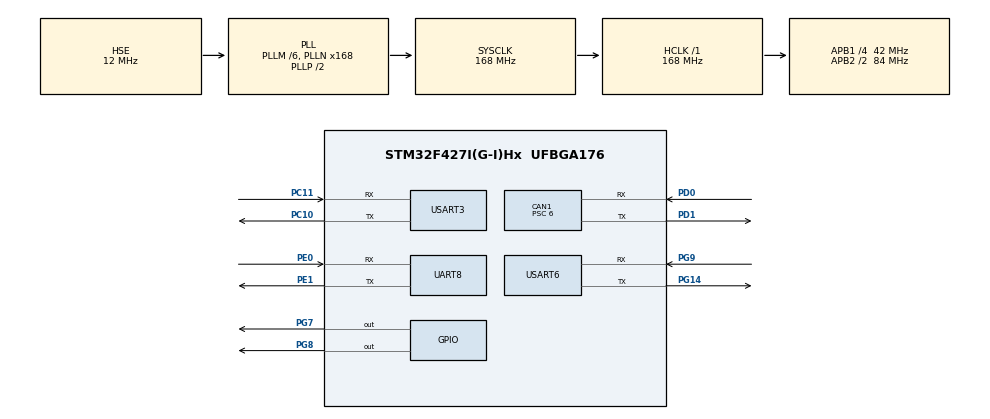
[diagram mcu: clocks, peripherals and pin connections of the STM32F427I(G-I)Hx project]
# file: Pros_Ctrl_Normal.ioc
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CAN1.BS1=CAN_BS1_4TQ
CAN1.BS2=CAN_BS2_2TQ
CAN1.CalculateBaudRate=1000000
CAN1.CalculateTimeBit=1000
CAN1.CalculateTimeQuantum=142.85714285714286
CAN1.Prescaler=6
Dma.Request0=USART6_RX
Dma.Request1=USART6_TX
Dma.Request2=USART3_RX
Dma.Request3=USART3_TX
Dma.Request4=UART8_TX
Dma.UART8_TX.4.Direction=DMA_MEMORY_TO_PERIPH
Dma.UART8_TX.4.FIFOMode=DMA_FIFOMODE_DISABLE
Dma.UART8_TX.4.Instance=DMA1_Stream0
Dma.UART8_TX.4.MemDataAlignment=DMA_MDATAALIGN_BYTE
Dma.UART8_TX.4.MemInc=DMA_MINC_ENABLE
Dma.UART8_TX.4.Mode=DMA_NORMAL
Dma.UART8_TX.4.PeriphDataAlignment=DMA_PDATAALIGN_BYTE
Dma.UART8_TX.4.PeriphInc=DMA_PINC_DISABLE
Dma.UART8_TX.4.Priority=DMA_PRIORITY_LOW
Dma.USART3_RX.2.Direction=DMA_PERIPH_TO_MEMORY
Dma.USART3_RX.2.FIFOMode=DMA_FIFOMODE_DISABLE
Dma.USART3_RX.2.Instance=DMA1_Stream1
Dma.USART3_RX.2.MemDataAlignment=DMA_MDATAALIGN_BYTE
Dma.USART3_RX.2.MemInc=DMA_MINC_ENABLE
Dma.USART3_RX.2.Mode=DMA_CIRCULAR
Dma.USART3_RX.2.PeriphDataAlignment=DMA_PDATAALIGN_BYTE
Dma.USART3_RX.2.PeriphInc=DMA_PINC_DISABLE
Dma.USART3_RX.2.Priority=DMA_PRIORITY_LOW
Dma.USART3_TX.3.Direction=DMA_MEMORY_TO_PERIPH
Dma.USART3_TX.3.FIFOMode=DMA_FIFOMODE_DISABLE
Dma.USART3_TX.3.Instance=DMA1_Stream3
Dma.USART3_TX.3.MemDataAlignment=DMA_MDATAALIGN_BYTE
Dma.USART3_TX.3.MemInc=DMA_MINC_ENABLE
Dma.USART3_TX.3.Mode=DMA_NORMAL
Dma.USART3_TX.3.PeriphDataAlignment=DMA_PDATAALIGN_BYTE
Dma.USART3_TX.3.PeriphInc=DMA_PINC_DISABLE
Dma.USART3_TX.3.Priority=DMA_PRIORITY_LOW
Dma.USART6_RX.0.Direction=DMA_PERIPH_TO_MEMORY
Dma.USART6_RX.0.FIFOMode=DMA_FIFOMODE_DISABLE
Dma.USART6_RX.0.Instance=DMA2_Stream1
Dma.USART6_RX.0.MemDataAlignment=DMA_MDATAALIGN_BYTE
Dma.USART6_RX.0.MemInc=DMA_MINC_ENABLE
Dma.USART6_RX.0.Mode=DMA_CIRCULAR
Dma.USART6_RX.0.PeriphDataAlignment=DMA_PDATAALIGN_BYTE
Dma.USART6_RX.0.PeriphInc=DMA_PINC_DISABLE
Dma.USART6_RX.0.Priority=DMA_PRIORITY_LOW
Dma.USART6_TX.1.Direction=DMA_MEMORY_TO_PERIPH
Dma.USART6_TX.1.FIFOMode=DMA_FIFOMODE_DISABLE
Dma.USART6_TX.1.Instance=DMA2_Stream6
Dma.USART6_TX.1.MemDataAlignment=DMA_MDATAALIGN_BYTE
Dma.USART6_TX.1.MemInc=DMA_MINC_ENABLE
Dma.USART6_TX.1.Mode=DMA_NORMAL
Dma.USART6_TX.1.PeriphDataAlignment=DMA_PDATAALIGN_BYTE
Dma.USART6_TX.1.PeriphInc=DMA_PINC_DISABLE
Dma.USART6_TX.1.Priority=DMA_PRIORITY_LOW
Mcu.Family=STM32F4
Mcu.Name=STM32F427I(G-I)Hx
Mcu.Package=UFBGA176
NVIC.CAN1_RX0_IRQn=true\:0\:0\:false\:false\:true\:true\:true\:true
NVIC.DMA1_Stream0_IRQn=true\:0\:0\:false\:false\:true\:false\:true\:true
NVIC.DMA1_Stream1_IRQn=true\:0\:0\:false\:false\:true\:false\:true\:true
NVIC.DMA1_Stream3_IRQn=true\:0\:0\:false\:false\:true\:false\:true\:true
NVIC.DMA2_Stream1_IRQn=true\:0\:0\:false\:false\:true\:false\:true\:true
NVIC.DMA2_Stream6_IRQn=true\:0\:0\:false\:false\:true\:false\:true\:true
NVIC.PriorityGroup=NVIC_PRIORITYGROUP_4
NVIC.TIM4_IRQn=true\:15\:0\:false\:false\:true\:false\:true\:true
NVIC.TimeBase=TIM4_IRQn
NVIC.TimeBaseIP=TIM4
NVIC.USART6_IRQn=true\:0\:0\:false\:false\:true\:true\:true\:true
PA13.Mode=Serial_Wire
PA13.Signal=SYS_JTMS-SWDIO
PA14.Mode=Serial_Wire
PA14.Signal=SYS_JTCK-SWCLK
PC10.Mode=Asynchronous
PC10.Signal=USART3_TX
PC11.Mode=Asynchronous
PC11.Signal=USART3_RX
PD0.Mode=CAN_Activate
PD0.Signal=CAN1_RX
PD1.Mode=CAN_Activate
PD1.Signal=CAN1_TX
PE0.Mode=Asynchronous
PE0.Signal=UART8_RX
PE1.Mode=Asynchronous
PE1.Signal=UART8_TX
PG14.Mode=Asynchronous
PG14.Signal=USART6_TX
PG7.Signal=GPIO_Output
PG8.Signal=GPIO_Output
PG9.Mode=Asynchronous
PG9.Signal=USART6_RX
PH0/OSC_IN.Mode=HSE-External-Oscillator
PH0/OSC_IN.Signal=RCC_OSC_IN
PH1/OSC_OUT.Mode=HSE-External-Oscillator
PH1/OSC_OUT.Signal=RCC_OSC_OUT
ProjectManager.HeapSize=0x200
ProjectManager.StackSize=0x400
ProjectManager.TargetToolchain=STM32CubeIDE
RCC.48MHZClocksFreq_Value=84000000
RCC.AHBFreq_Value=168000000
RCC.APB1CLKDivider=RCC_HCLK_DIV4
RCC.APB1Freq_Value=42000000
RCC.APB1TimFreq_Value=84000000
RCC.APB2CLKDivider=RCC_HCLK_DIV2
RCC.APB2Freq_Value=84000000
RCC.APB2TimFreq_Value=168000000
RCC.CortexFreq_Value=168000000
RCC.HCLKFreq_Value=168000000
RCC.HSE_VALUE=12000000
RCC.HSI_VALUE=16000000
RCC.LSE_VALUE=32768
RCC.PLLM=6
RCC.PLLN=168
RCC.PLLSourceVirtual=RCC_PLLSOURCE_HSE
RCC.SYSCLKFreq_VALUE=168000000
RCC.SYSCLKSource=RCC_SYSCLKSOURCE_PLLCLK
RCC.VCOOutputFreq_Value=336000000
UART8.VirtualMode=Asynchronous
USART3.VirtualMode=VM_ASYNC
USART6.VirtualMode=VM_ASYNC
VP_SYS_VS_tim4.Mode=TIM4
board=custom

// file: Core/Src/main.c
/* USER CODE BEGIN Header */
/**
  ******************************************************************************
  * @file           : main.c
  * @brief          : Main program body
  ******************************************************************************
  * @attention
  *
  * Copyright (c) 2023 STMicroelectronics.
  * All rights reserved.
  *
  * This software is licensed under terms that can be found in the LICENSE file
  * in the root directory of this software component.
  * If no LICENSE file comes with this software, it is provided AS-IS.
  *
  ******************************************************************************
  */
/* USER CODE END Header */
#include "main.h"
#include "can.h"
#include "dma.h"
#include "usart.h"
#include "gpio.h"

/* USER CODE BEGIN Includes */
#include "motor.h"
#include "uart_communication.h"
/* USER CODE END Includes */

void SystemClock_Config(void);

int main(void)
{

  /* MCU Configuration--------------------------------------------------------*/

  /* Reset of all peripherals, Initializes the Flash interface and the Systick. */
  HAL_Init();

  /* Configure the system clock */
  SystemClock_Config();

  /* Initialize all configured peripherals */
  MX_GPIO_Init();
  MX_DMA_Init();
  MX_USART6_UART_Init();
  MX_USART3_UART_Init();
  MX_CAN1_Init();
  MX_UART8_Init();
  /* USER CODE BEGIN 2 */
  CAN_FilterConfig();
  motor_init();
  Start_PCReceiveIT();
  /* USER CODE END 2 */

  /* Infinite loop */
  while (1)
  {

    /* USER CODE BEGIN 3 */
	  PC_PackMessage();
	  HAL_Delay(10);
	  Motor_Debug_CMDUnpack();
	  debugPrint("Hello\r\n");
  }
  /* USER CODE END 3 */
}

void SystemClock_Config(void)
{
  RCC_OscInitTypeDef RCC_OscInitStruct = {0};
  RCC_ClkInitTypeDef RCC_ClkInitStruct = {0};

  /** Configure the main internal regulator output voltage
  */
  __HAL_RCC_PWR_CLK_ENABLE();
  __HAL_PWR_VOLTAGESCALING_CONFIG(PWR_REGULATOR_VOLTAGE_SCALE1);

  /** Initializes the RCC Oscillators according to the specified parameters
  * in the RCC_OscInitTypeDef structure.
  */
  RCC_OscInitStruct.OscillatorType = RCC_OSCILLATORTYPE_HSE;
  RCC_OscInitStruct.HSEState = RCC_HSE_ON;
  RCC_OscInitStruct.PLL.PLLState = RCC_PLL_ON;
  RCC_OscInitStruct.PLL.PLLSource = RCC_PLLSOURCE_HSE;
  RCC_OscInitStruct.PLL.PLLM = 6;
  RCC_OscInitStruct.PLL.PLLN = 168;
  RCC_OscInitStruct.PLL.PLLP = RCC_PLLP_DIV2;
  RCC_OscInitStruct.PLL.PLLQ = 4;
  if (HAL_RCC_OscConfig(&RCC_OscInitStruct) != HAL_OK)
  {
    Error_Handler();
  }

  /** Initializes the CPU, AHB and APB buses clocks
  */
  RCC_ClkInitStruct.ClockType = RCC_CLOCKTYPE_HCLK|RCC_CLOCKTYPE_SYSCLK
                              |RCC_CLOCKTYPE_PCLK1|RCC_CLOCKTYPE_PCLK2;
  RCC_ClkInitStruct.SYSCLKSource = RCC_SYSCLKSOURCE_PLLCLK;
  RCC_ClkInitStruct.AHBCLKDivider = RCC_SYSCLK_DIV1;
  RCC_ClkInitStruct.APB1CLKDivider = RCC_HCLK_DIV4;
  RCC_ClkInitStruct.APB2CLKDivider = RCC_HCLK_DIV2;

  if (HAL_RCC_ClockConfig(&RCC_ClkInitStruct, FLASH_LATENCY_5) != HAL_OK)
  {
    Error_Handler();
  }
}

void HAL_TIM_PeriodElapsedCallback(TIM_HandleTypeDef *htim)
{
  if (htim->Instance == TIM4) {
    HAL_IncTick();
  }
}

void Error_Handler(void)
{
  __disable_irq();
  while (1)
  {
  }
}
